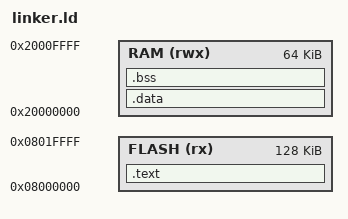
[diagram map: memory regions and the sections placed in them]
/* Minimal linker script for Cortex-M device */
ENTRY(Reset_Handler)

MEMORY
{
  FLASH (rx) : ORIGIN = 0x08000000, LENGTH = 128K
  RAM (rwx)  : ORIGIN = 0x20000000, LENGTH = 64K
}

SECTIONS
{
  .text :
  {
    KEEP(*(.isr_vector))
    *(.text*)
    *(.rodata*)
    _etext = .;
  } > FLASH

  .data : AT (_etext)
  {
    _sidata = LOADADDR(.data);
    _sdata = .;
    *(.data*)
    _edata = .;
  } > RAM

  .bss :
  {
    _sbss = .;
    *(.bss*)
    *(COMMON)
    _ebss = .;
  } > RAM

  /DISCARD/ : { *(.eh_frame*) }
}
